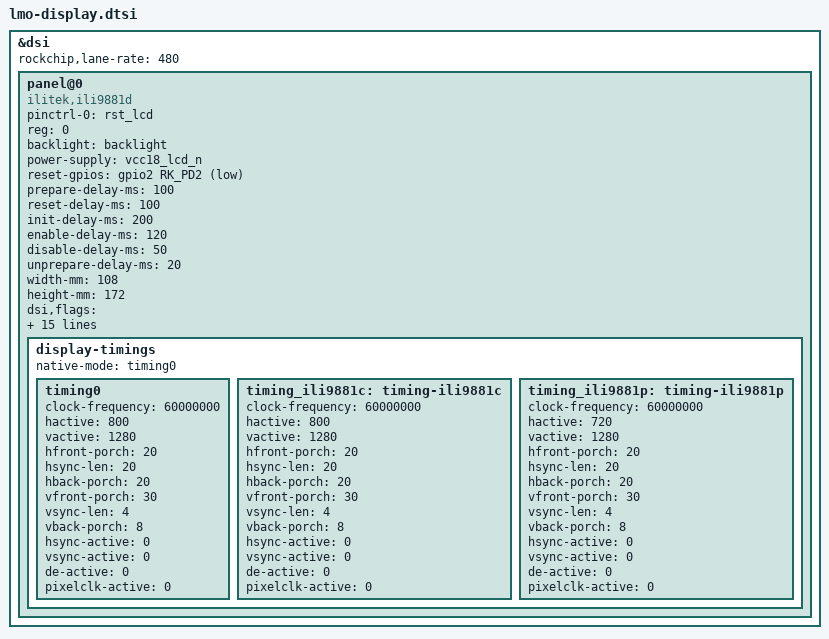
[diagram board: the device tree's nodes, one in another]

&dsi {
	status = "okay";

	rockchip,lane-rate = <480>;
	panel@0 {
		compatible = "ilitek,ili9881d", "simple-panel-dsi";
		pinctrl-names = "default";
		pinctrl-0 = <&rst_lcd>;
		reg = <0>;
		backlight = <&backlight>;
		power-supply = <&vcc18_lcd_n>;
		reset-gpios = <&gpio2 RK_PD2 GPIO_ACTIVE_LOW>;
		prepare-delay-ms = <100>;
		reset-delay-ms = <100>;
		init-delay-ms = <200>;
		enable-delay-ms = <120>;
		disable-delay-ms = <50>;
		unprepare-delay-ms = <20>;

		width-mm = <108>;
		height-mm = <172>;

		dsi,flags = <(MIPI_DSI_MODE_VIDEO | MIPI_DSI_MODE_VIDEO_BURST |
			      MIPI_DSI_MODE_LPM | MIPI_DSI_MODE_NO_EOT_PACKET)>;
		dsi,format = <MIPI_DSI_FMT_RGB888>;
		dsi,lanes = <4>;

		panel-init-sequence = [
			39 00 04 FF 98 81 03
			15 00 02 01 00
			15 00 02 02 00
			15 00 02 03 73
			15 00 02 04 D7
			15 00 02 05 00
			15 00 02 06 08
			15 00 02 07 11
			15 00 02 08 00
			15 00 02 09 3F
			15 00 02 0A 00
			15 00 02 0B 00
			15 00 02 0C 00
			15 00 02 0D 00
			15 00 02 0E 00
			15 00 02 0F 3F
			15 00 02 10 3F
			15 00 02 11 00
			15 00 02 12 00
			15 00 02 13 00
			15 00 02 14 00
			15 00 02 15 00
			15 00 02 16 00
			15 00 02 17 00
			15 00 02 18 00
			15 00 02 19 00
			15 00 02 1A 00
			15 00 02 1B 00
			15 00 02 1C 00
			15 00 02 1D 00
			15 00 02 1E 40
			15 00 02 1F 80
			15 00 02 20 06
			15 00 02 21 01
			15 00 02 22 00
			15 00 02 23 00
			15 00 02 24 00
			15 00 02 25 00
			15 00 02 26 00
			15 00 02 27 00
			15 00 02 28 33
			15 00 02 29 33
			15 00 02 2A 00
			15 00 02 2B 00
			15 00 02 2C 00
			15 00 02 2D 00
			15 00 02 2E 00
			15 00 02 2F 00
			15 00 02 30 00
			15 00 02 31 00
			15 00 02 32 00
			15 00 02 33 00
			15 00 02 34 00
			15 00 02 35 00
			15 00 02 36 00
			15 00 02 37 00
			15 00 02 38 00
			15 00 02 39 00
			15 00 02 3A 00
			15 00 02 3B 00
			15 00 02 3C 00
			15 00 02 3D 00
			15 00 02 3E 00
			15 00 02 3F 00
			15 00 02 40 00
			15 00 02 41 00
			15 00 02 42 00
			15 00 02 43 00
			15 00 02 44 00
			15 00 02 50 01
			15 00 02 51 23
			15 00 02 52 44
			15 00 02 53 67
			15 00 02 54 89
			15 00 02 55 AB
			15 00 02 56 01
			15 00 02 57 23
			15 00 02 58 45
			15 00 02 59 67
			15 00 02 5A 89
			15 00 02 5B AB
			15 00 02 5C CD
			15 00 02 5D EF
			15 00 02 5E 00
			15 00 02 5F 0C
			15 00 02 60 0C
			15 00 02 61 0F
			15 00 02 62 0F
			15 00 02 63 0E
			15 00 02 64 0E
			15 00 02 65 06
			15 00 02 66 07
			15 00 02 67 0D
			15 00 02 68 02
			15 00 02 69 02
			15 00 02 6A 02
			15 00 02 6B 02
			15 00 02 6C 02
			15 00 02 6D 02
			15 00 02 6E 0D
			15 00 02 6F 02
			15 00 02 70 02
			15 00 02 71 05
			15 00 02 72 01
			15 00 02 73 08
			15 00 02 74 00
			15 00 02 75 0C
			15 00 02 76 0C
			15 00 02 77 0F
			15 00 02 78 0F
			15 00 02 79 0E
			15 00 02 7A 0E
			15 00 02 7B 06
			15 00 02 7C 07
			15 00 02 7D 0D
			15 00 02 7E 02
			15 00 02 7F 02
			15 00 02 80 02
			15 00 02 81 02
			15 00 02 82 02
			15 00 02 83 02
			15 00 02 84 0D
			15 00 02 85 02
			15 00 02 86 02
			15 00 02 87 05
			15 00 02 88 01
			15 00 02 89 08
			15 00 02 8A 00
			39 00 04 FF 98 81 04
			15 00 02 6E 3B
			15 00 02 6F 57
			15 00 02 3A A4
			15 00 02 8D 1F
			15 00 02 87 BA
			15 00 02 B2 D1
			15 00 02 88 0B
			15 00 02 38 01
			15 00 02 39 00
			15 00 02 B5 07
			15 00 02 31 75
			15 00 02 3B 98
			39 00 04 FF 98 81 01
			15 00 02 22 0A
			15 00 02 31 09
			15 00 02 53 62
			15 00 02 55 40
			15 00 02 50 86
			15 00 02 51 82
			15 00 02 60 27
			15 00 02 62 20
			15 00 02 A0 00
			15 00 02 A1 11
			15 00 02 A2 1F
			15 00 02 A3 13
			15 00 02 A4 14
			15 00 02 A5 28
			15 00 02 A6 1D
			15 00 02 A7 1F
			15 00 02 A8 7A
			15 00 02 A9 1C
			15 00 02 AA 2A
			15 00 02 AB 69
			15 00 02 AC 1A
			15 00 02 AD 18
			15 00 02 AE 4D
			15 00 02 AF 22
			15 00 02 B0 29
			15 00 02 B1 4C
			15 00 02 B2 5B
			15 00 02 B3 23
			15 00 02 C0 00
			15 00 02 C1 12
			15 00 02 C2 1F
			15 00 02 C3 12
			15 00 02 C4 15
			15 00 02 C5 29
			15 00 02 C6 1D
			15 00 02 C7 1E
			15 00 02 C8 78
			15 00 02 C9 1D
			15 00 02 CA 29
			15 00 02 CB 69
			15 00 02 CC 19
			15 00 02 CD 18
			15 00 02 CE 4C
			15 00 02 CF 21
			15 00 02 D0 29
			15 00 02 D1 4C
			15 00 02 D2 5B
			15 00 02 D3 23
			39 00 04 FF 98 81 00
			15 C8 02 11 00
			15 C8 02 29 00
		];

		panel-init-sequence-jd9365da = [
			15 00 02 E1 93
			15 00 02 E2 65
			15 00 02 E3 F8
			15 00 02 80 03
			15 00 02 E0 01
			15 00 02 00 00
			15 00 02 01 2A
			15 00 02 03 00
			15 00 02 04 30
			15 00 02 17 00
			15 00 02 18 E7
			15 00 02 19 00
			15 00 02 1A 00
			15 00 02 1B E7
			15 00 02 1C 00
			15 00 02 35 23
			15 00 02 37 09
			15 00 02 38 04
			15 00 02 39 08
			15 00 02 3A 12
			15 00 02 3C 78
			15 00 02 3D FF
			15 00 02 3E FF
			15 00 02 3F FF
			15 00 02 40 06
			15 00 02 41 A0
			15 00 02 43 14
			15 00 02 44 0F
			15 00 02 45 30
			15 00 02 4B 04
			15 00 02 55 02
			15 00 02 57 65
			15 00 02 59 0A
			15 00 02 5A 28
			15 00 02 5B 15
			15 00 02 5D 7C
			15 00 02 5E 5A
			15 00 02 5F 45
			15 00 02 60 36
			15 00 02 61 2F
			15 00 02 62 20
			15 00 02 63 24
			15 00 02 64 0F
			15 00 02 65 2C
			15 00 02 66 2E
			15 00 02 67 31
			15 00 02 68 52
			15 00 02 69 40
			15 00 02 6A 49
			15 00 02 6B 3E
			15 00 02 6C 3B
			15 00 02 6D 30
			15 00 02 6E 21
			15 00 02 6F 0C
			15 00 02 70 7C
			15 00 02 71 5A
			15 00 02 72 45
			15 00 02 73 36
			15 00 02 74 2F
			15 00 02 75 20
			15 00 02 76 24
			15 00 02 77 0F
			15 00 02 78 2C
			15 00 02 79 2E
			15 00 02 7A 31
			15 00 02 7B 52
			15 00 02 7C 40
			15 00 02 7D 49
			15 00 02 7E 3E
			15 00 02 7F 3B
			15 00 02 80 30
			15 00 02 81 21
			15 00 02 82 0C
			15 00 02 E0 02
			15 00 02 00 5F
			15 00 02 01 5F
			15 00 02 02 53
			15 00 02 03 51
			15 00 02 04 4B
			15 00 02 05 49
			15 00 02 06 47
			15 00 02 07 45
			15 00 02 08 41
			15 00 02 09 43
			15 00 02 0A 5F
			15 00 02 0B 5F
			15 00 02 0C 5F
			15 00 02 0D 5F
			15 00 02 0E 5F
			15 00 02 0F 5F
			15 00 02 10 5F
			15 00 02 11 5F
			15 00 02 12 5F
			15 00 02 13 5F
			15 00 02 14 5F
			15 00 02 15 5F
			15 00 02 16 5F
			15 00 02 17 5F
			15 00 02 18 52
			15 00 02 19 50
			15 00 02 1A 4A
			15 00 02 1B 48
			15 00 02 1C 46
			15 00 02 1D 44
			15 00 02 1E 40
			15 00 02 1F 42
			15 00 02 20 5F
			15 00 02 21 5F
			15 00 02 22 5F
			15 00 02 23 5F
			15 00 02 24 5F
			15 00 02 25 5F
			15 00 02 26 5F
			15 00 02 27 5F
			15 00 02 28 5F
			15 00 02 29 5F
			15 00 02 2A 5F
			15 00 02 2B 5F
			15 00 02 2C 1F
			15 00 02 2D 1F
			15 00 02 2E 00
			15 00 02 2F 02
			15 00 02 30 08
			15 00 02 31 0A
			15 00 02 32 04
			15 00 02 33 06
			15 00 02 34 12
			15 00 02 35 10
			15 00 02 36 1F
			15 00 02 37 1F
			15 00 02 38 1F
			15 00 02 39 1F
			15 00 02 3A 1F
			15 00 02 3B 1F
			15 00 02 3C 1F
			15 00 02 3D 1F
			15 00 02 3E 1F
			15 00 02 3F 1F
			15 00 02 40 1F
			15 00 02 41 1F
			15 00 02 42 1F
			15 00 02 43 1F
			15 00 02 44 01
			15 00 02 45 03
			15 00 02 46 09
			15 00 02 47 0B
			15 00 02 48 05
			15 00 02 49 07
			15 00 02 4A 13
			15 00 02 4B 11
			15 00 02 4C 1F
			15 00 02 4D 1F
			15 00 02 4E 1F
			15 00 02 4F 1F
			15 00 02 50 1F
			15 00 02 51 1F
			15 00 02 52 1F
			15 00 02 53 1F
			15 00 02 54 1F
			15 00 02 55 1F
			15 00 02 56 1F
			15 00 02 57 1F
			15 00 02 58 40
			15 00 02 59 00
			15 00 02 5A 00
			15 00 02 5B 30
			15 00 02 5C 09
			15 00 02 5D 30
			15 00 02 5E 01
			15 00 02 5F 02
			15 00 02 60 30
			15 00 02 61 03
			15 00 02 62 04
			15 00 02 63 1C
			15 00 02 64 6A
			15 00 02 65 75
			15 00 02 66 0d
			15 00 02 67 72
			15 00 02 68 0c
			15 00 02 69 1C
			15 00 02 6A 6A
			15 00 02 6B 08
			15 00 02 6C 00
			15 00 02 6D 00
			15 00 02 6E 00
			15 00 02 6F 88
			15 00 02 70 00
			15 00 02 71 00
			15 00 02 72 06
			15 00 02 73 7B
			15 00 02 74 00
			15 00 02 75 BB
			15 00 02 76 01
			15 00 02 77 0D
			15 00 02 78 24
			15 00 02 79 00
			15 00 02 7A 00
			15 00 02 7B 00
			15 00 02 7C 00
			15 00 02 7D 03
			15 00 02 7E 7B
			15 00 02 E0 04
			15 00 02 00 0E
			15 00 02 02 B3
			15 00 02 0E 4A
			15 00 02 E0 00
			05 C8 01 11
			05 14 01 29
		];

		panel-init-sequence-jd9365d = [
			15 00 02 E0 00

			15 00 02 E1 93
			15 00 02 E2 65
			15 00 02 E3 F8
			15 00 02 80 03

			15 00 02 E0 01

			15 00 02 00 00
			15 00 02 01 3C
			15 00 02 03 00
			15 00 02 04 3C

			15 00 02 0C 74
			15 00 02 17 00
			15 00 02 18 F7
			15 00 02 19 01
			15 00 02 1A 00
			15 00 02 1B F7
			15 00 02 1C 01

			15 00 02 24 F1

			15 00 02 35 23

			15 00 02 37 09

			15 00 02 38 04
			15 00 02 39 00
			15 00 02 3A 01
			15 00 02 3C 70
			15 00 02 3D FF
			15 00 02 3E FF
			15 00 02 3F 7F

			15 00 02 40 06
			15 00 02 41 A0
			15 00 02 43 1E
			15 00 02 44 0B
			15 00 02 45 28

			15 00 02 55 01
			15 00 02 57 A9
			15 00 02 59 0A
			15 00 02 5A 2D
			15 00 02 5B 1A
			15 00 02 5C 15

			15 00 02 5D 7F
			15 00 02 5E 69
			15 00 02 5F 59
			15 00 02 60 4C
			15 00 02 61 47
			15 00 02 62 38
			15 00 02 63 3D
			15 00 02 64 27
			15 00 02 65 41
			15 00 02 66 40
			15 00 02 67 40
			15 00 02 68 5B
			15 00 02 69 46
			15 00 02 6A 49
			15 00 02 6B 3A
			15 00 02 6C 34
			15 00 02 6D 25
			15 00 02 6E 15
			15 00 02 6F 02
			15 00 02 70 7F
			15 00 02 71 69
			15 00 02 72 59
			15 00 02 73 4C
			15 00 02 74 47
			15 00 02 75 38
			15 00 02 76 3D
			15 00 02 77 27
			15 00 02 78 41
			15 00 02 79 40
			15 00 02 7A 40
			15 00 02 7B 5B
			15 00 02 7C 46
			15 00 02 7D 49
			15 00 02 7E 3A
			15 00 02 7F 34
			15 00 02 80 25
			15 00 02 81 15
			15 00 02 82 02

			15 00 02 E0 02

			15 00 02 00 50
			15 00 02 01 5F
			15 00 02 02 5F
			15 00 02 03 52
			15 00 02 04 77
			15 00 02 05 57
			15 00 02 06 5F
			15 00 02 07 4E
			15 00 02 08 4C
			15 00 02 09 5F
			15 00 02 0A 4A
			15 00 02 0B 48
			15 00 02 0C 5F
			15 00 02 0D 46
			15 00 02 0E 44
			15 00 02 0F 40
			15 00 02 10 5F
			15 00 02 11 5F
			15 00 02 12 5F
			15 00 02 13 5F
			15 00 02 14 5F
			15 00 02 15 5F

			15 00 02 16 51
			15 00 02 17 5F
			15 00 02 18 5F
			15 00 02 19 53
			15 00 02 1A 77
			15 00 02 1B 57
			15 00 02 1C 5F
			15 00 02 1D 4F
			15 00 02 1E 4D
			15 00 02 1F 5F
			15 00 02 20 4B
			15 00 02 21 49
			15 00 02 22 5F
			15 00 02 23 47
			15 00 02 24 45
			15 00 02 25 41
			15 00 02 26 5F
			15 00 02 27 5F
			15 00 02 28 5F
			15 00 02 29 5F
			15 00 02 2A 5F
			15 00 02 2B 5F

			15 00 02 2C 01
			15 00 02 2D 1F
			15 00 02 2E 1F
			15 00 02 2F 13
			15 00 02 30 17
			15 00 02 31 17
			15 00 02 32 1F
			15 00 02 33 0D
			15 00 02 34 0F
			15 00 02 35 1F
			15 00 02 36 05
			15 00 02 37 07
			15 00 02 38 1F
			15 00 02 39 09
			15 00 02 3A 0B
			15 00 02 3B 11
			15 00 02 3C 1F
			15 00 02 3D 1F
			15 00 02 3E 1F
			15 00 02 3F 1F
			15 00 02 40 1F
			15 00 02 41 1F

			15 00 02 42 00
			15 00 02 43 1F
			15 00 02 44 1F
			15 00 02 45 12
			15 00 02 46 17
			15 00 02 47 17
			15 00 02 48 1F
			15 00 02 49 0C
			15 00 02 4A 0E
			15 00 02 4B 1F
			15 00 02 4C 04
			15 00 02 4D 06
			15 00 02 4E 1F
			15 00 02 4F 08
			15 00 02 50 0A
			15 00 02 51 10
			15 00 02 52 1F
			15 00 02 53 1F
			15 00 02 54 1F
			15 00 02 55 1F
			15 00 02 56 1F
			15 00 02 57 1F

			15 00 02 58 40
			15 00 02 5B 10
			15 00 02 5C 06
			15 00 02 5D 40
			15 00 02 5E 00
			15 00 02 5F 00
			15 00 02 60 40
			15 00 02 61 03
			15 00 02 62 04
			15 00 02 63 6C
			15 00 02 64 6C
			15 00 02 65 75
			15 00 02 66 08
			15 00 02 67 B4
			15 00 02 68 08
			15 00 02 69 6C
			15 00 02 6A 6C
			15 00 02 6B 0C
			15 00 02 6D 00
			15 00 02 6E 00
			15 00 02 6F 88
			15 00 02 75 BB
			15 00 02 76 00
			15 00 02 77 05
			15 00 02 78 2A

			15 00 02 E0 04
			15 00 02 09 11
			15 00 02 0E 48
			15 00 02 2B 08
			15 00 02 2D 03
			15 00 02 2E 03

			15 00 02 E0 00

			15 78 02 11 00
			15 05 02 29 00
		];

		panel-init-sequence-ili9881c = [
			39 00 04 FF 98 81 03
			15 00 02 01 00
			15 00 02 02 00
			15 00 02 03 73
			15 00 02 04 00
			15 00 02 05 00
			15 00 02 06 08
			15 00 02 07 00
			15 00 02 08 00
			15 00 02 09 00
			15 00 02 0A 01
			15 00 02 0B 01
			15 00 02 0C 00
			15 00 02 0D 01
			15 00 02 0E 01
			15 00 02 0F 00
			15 00 02 10 00
			15 00 02 11 00
			15 00 02 12 00
			15 00 02 13 1F
			15 00 02 14 1F
			15 00 02 15 00
			15 00 02 16 00
			15 00 02 17 00
			15 00 02 18 00
			15 00 02 19 00
			15 00 02 1A 00
			15 00 02 1B 00
			15 00 02 1C 00
			15 00 02 1D 00
			15 00 02 1E 40
			15 00 02 1F C0
			15 00 02 20 06
			15 00 02 21 01
			15 00 02 22 06
			15 00 02 23 01
			15 00 02 24 88
			15 00 02 25 88
			15 00 02 26 00
			15 00 02 27 00
			15 00 02 28 3B
			15 00 02 29 03
			15 00 02 2A 00
			15 00 02 2B 00
			15 00 02 2C 00
			15 00 02 2D 00
			15 00 02 2E 00
			15 00 02 2F 00
			15 00 02 30 00
			15 00 02 31 00
			15 00 02 32 00
			15 00 02 33 00
			15 00 02 34 00
			15 00 02 35 00
			15 00 02 36 00
			15 00 02 37 00
			15 00 02 38 00
			15 00 02 39 00
			15 00 02 3A 00
			15 00 02 3B 00
			15 00 02 3C 00
			15 00 02 3D 00
			15 00 02 3E 00
			15 00 02 3F 00
			15 00 02 40 00
			15 00 02 41 00
			15 00 02 42 00
			15 00 02 43 00
			15 00 02 44 00
			15 00 02 50 01
			15 00 02 51 23
			15 00 02 52 45
			15 00 02 53 67
			15 00 02 54 89
			15 00 02 55 AB
			15 00 02 56 01
			15 00 02 57 23
			15 00 02 58 45
			15 00 02 59 67
			15 00 02 5A 89
			15 00 02 5B AB
			15 00 02 5C CD
			15 00 02 5D EF
			15 00 02 5E 00
			15 00 02 5F 01
			15 00 02 60 01
			15 00 02 61 06
			15 00 02 62 06
			15 00 02 63 07
			15 00 02 64 07
			15 00 02 65 00
			15 00 02 66 00
			15 00 02 67 02
			15 00 02 68 02
			15 00 02 69 05
			15 00 02 6A 05
			15 00 02 6B 02
			15 00 02 6C 0D
			15 00 02 6D 0D
			15 00 02 6E 0C
			15 00 02 6F 0C
			15 00 02 70 0F
			15 00 02 71 0F
			15 00 02 72 0E
			15 00 02 73 0E
			15 00 02 74 02
			15 00 02 75 01
			15 00 02 76 01
			15 00 02 77 06
			15 00 02 78 06
			15 00 02 79 07
			15 00 02 7A 07
			15 00 02 7B 00
			15 00 02 7C 00
			15 00 02 7D 02
			15 00 02 7E 02
			15 00 02 7F 05
			15 00 02 80 05
			15 00 02 81 02
			15 00 02 82 0D
			15 00 02 83 0D
			15 00 02 84 0C
			15 00 02 85 0C
			15 00 02 86 0F
			15 00 02 87 0F
			15 00 02 88 0E
			15 00 02 89 0E
			15 00 02 8A 02
			39 00 04 FF 98 81 04
			15 00 02 6C 15
			15 00 02 6E 2A
			15 00 02 6F 33
			15 00 02 8D 1B
			15 00 02 87 BA
			15 00 02 3A 24
			15 00 02 26 76
			15 00 02 B2 D1
			39 00 04 FF 98 81 01
			15 00 02 22 0A
			15 00 02 31 00                  
			15 00 02 43 66
			15 00 02 53 42
			15 00 02 50 87
			15 00 02 51 82
			15 00 02 60 15
			15 00 02 61 01
			15 00 02 62 0C
			15 00 02 63 00
			15 00 02 A0 00
			15 00 02 A1 13
			15 00 02 A2 23
			15 00 02 A3 14
			15 00 02 A4 16
			15 00 02 A5 29
			15 00 02 A6 1E
			15 00 02 A7 1D
			15 00 02 A8 86
			15 00 02 A9 1E
			15 00 02 AA 29
			15 00 02 AB 74
			15 00 02 AC 19
			15 00 02 AD 17
			15 00 02 AE 4B
			15 00 02 AF 20
			15 00 02 B0 26
			15 00 02 B1 4C
			15 00 02 B2 5D
			15 00 02 B3 3F
			15 00 02 C0 00
			15 00 02 C1 13
			15 00 02 C2 23
			15 00 02 C3 14
			15 00 02 C4 16
			15 00 02 C5 29
			15 00 02 C6 1E
			15 00 02 C7 1D
			15 00 02 C8 86
			15 00 02 C9 1E
			15 00 02 CA 29
			15 00 02 CB 74
			15 00 02 CC 19
			15 00 02 CD 17
			15 00 02 CE 4B
			15 00 02 CF 20
			15 00 02 D0 26
			15 00 02 D1 4C
			15 00 02 D2 5D
			15 00 02 D3 3F
			39 00 04 FF 98 81 00
			15 00 02 35 00
			05 78 01 11
			05 14 01 29
		];

		panel-init-sequence-ili9881p = [//720x1280
			39 00 04 FF 98 81 01
			15 00 02 01 00
			15 00 02 02 00
			15 00 02 03 56
			15 00 02 04 13
			15 00 02 05 13
			15 00 02 06 0a
			15 00 02 07 05
			15 00 02 08 05
			15 00 02 09 1D
			15 00 02 0a 01
			15 00 02 0b 00
			15 00 02 0c 3F
			15 00 02 0d 29
			15 00 02 0e 29
			15 00 02 0f 1D
			15 00 02 10 1D
			15 00 02 11 00
			15 00 02 12 00
			15 00 02 13 08
			15 00 02 14 08
			15 00 02 15 00
			15 00 02 16 00
			15 00 02 17 00
			15 00 02 18 00
			15 00 02 19 00
			15 00 02 1a 00
			15 00 02 1b 00
			15 00 02 1c 00
			15 00 02 1d 00
			15 00 02 1e 40
			15 00 02 1f 88
			15 00 02 20 08
			15 00 02 21 01
			15 00 02 22 00
			15 00 02 23 00
			15 00 02 24 00
			15 00 02 25 00
			15 00 02 26 00
			15 00 02 27 00
			15 00 02 28 33
			15 00 02 29 03
			15 00 02 2a 00
			15 00 02 2b 00
			15 00 02 2c 00
			15 00 02 2d 00
			15 00 02 2e 00
			15 00 02 2f 00
			15 00 02 30 00
			15 00 02 31 00
			15 00 02 32 00
			15 00 02 33 00
			15 00 02 34 00
			15 00 02 35 00
			15 00 02 36 00
			15 00 02 37 00
			15 00 02 38 00
			15 00 02 39 0f
			15 00 02 3a 2a
			15 00 02 3b 00
			15 00 02 3c 00
			15 00 02 3d 00
			15 00 02 3e 00
			15 00 02 3f 00
			15 00 02 40 00
			15 00 02 41 e0
			15 00 02 42 40
			15 00 02 43 0f
			15 00 02 44 11
			15 00 02 45 a8
			15 00 02 46 00
			15 00 02 47 08
			15 00 02 48 00
			15 00 02 49 01
			15 00 02 4a 00
			15 00 02 4b 00
			15 00 02 4c b2
			15 00 02 4d 22
			15 00 02 4e 07
			15 00 02 4f f1
			15 00 02 50 29
			15 00 02 51 72
			15 00 02 52 25
			15 00 02 53 b2
			15 00 02 54 22
			15 00 02 55 22
			15 00 02 56 22
			15 00 02 57 a2
			15 00 02 58 22
			15 00 02 59 06
			15 00 02 5a e1
			15 00 02 5b 28
			15 00 02 5c 62
			15 00 02 5d 24
			15 00 02 5e a2
			15 00 02 5f 22
			15 00 02 60 22
			15 00 02 61 22
			15 00 02 62 ee
			15 00 02 63 02
			15 00 02 64 0b
			15 00 02 65 02
			15 00 02 66 02
			15 00 02 67 0F
			15 00 02 68 00
			15 00 02 69 01
			15 00 02 6a 07
			15 00 02 6b 55
			15 00 02 6c 02
			15 00 02 6d 02
			15 00 02 6e 5b
			15 00 02 6f 59
			15 00 02 70 02
			15 00 02 71 02
			15 00 02 72 57
			15 00 02 73 02
			15 00 02 74 02
			15 00 02 75 02
			15 00 02 76 02
			15 00 02 77 02
			15 00 02 78 02
			15 00 02 79 02
			15 00 02 7a 0a
			15 00 02 7b 02
			15 00 02 7c 02
			15 00 02 7d 0E
			15 00 02 7e 00
			15 00 02 7f 01
			15 00 02 80 06
			15 00 02 81 54
			15 00 02 82 02
			15 00 02 83 02
			15 00 02 84 5a
			15 00 02 85 58
			15 00 02 86 02
			15 00 02 87 02
			15 00 02 88 56
			15 00 02 89 02
			15 00 02 8a 02
			15 00 02 8b 02
			15 00 02 8c 02
			15 00 02 8d 02
			15 00 02 8e 02
			15 00 02 8f 44
			15 00 02 90 44
			39 00 04 FF 98 81 02
			15 00 02 01 50
			15 00 02 15 10
			15 00 02 42 01
			39 00 15 57 00 1A 29 13 17 2B 1F 20 8E 1E 2A 76 1A 17 4B 21 27 45 53 24
			39 00 15 6B 00 1A 29 13 17 2B 1F 20 8E 1E 2A 76 1A 17 4B 21 27 45 53 24
			39 00 04 FF 98 81 05
			15 00 02 03 00
			15 00 02 04 1E
			15 00 02 1A 50
			15 00 02 1B 09
			15 00 02 1E 11
			15 00 02 26 0E
			15 00 02 38 A0
			15 00 02 4C 11
			15 00 02 4D 22
			15 00 02 54 28
			15 00 02 55 25
			15 00 02 78 01
			15 00 02 A9 C0
			15 00 02 B1 70
			15 00 02 B2 70
			39 00 04 FF 98 81 06
			15 00 02 01 03
			15 00 02 2B 0A
			15 00 02 04 70
			15 00 02 C0 7F
			15 00 02 C1 2A
			39 00 04 FF 98 81 00
			15 C8 02 11 00
			15 14 02 29 00
			15 00 02 35 00
			15 00 02 36 00
		];

		panel-exit-sequence = [
			15 00 02 28 00
			15 00 02 10 00
		];

		display-timings {
			native-mode = <&timing0>;

			timing0: timing0 {
				clock-frequency = <60000000>;
				hactive = <800>;
				vactive = <1280>;
				hfront-porch = <20>;
				hsync-len = <20>;
				hback-porch = <20>;
				vfront-porch = <30>;
				vsync-len = <4>;
				vback-porch = <8>;
				hsync-active = <0>;
				vsync-active = <0>;
				de-active = <0>;
				pixelclk-active = <0>;
			};

			timing_ili9881c: timing-ili9881c {
				clock-frequency = <60000000>;
				hactive = <800>;
				vactive = <1280>;
				hfront-porch = <20>;
				hsync-len = <20>;
				hback-porch = <20>;
				vfront-porch = <30>;
				vsync-len = <4>;
				vback-porch = <8>;
				hsync-active = <0>;
				vsync-active = <0>;
				de-active = <0>;
				pixelclk-active = <0>;
			};

			timing_ili9881p: timing-ili9881p {
				clock-frequency = <60000000>;
				hactive = <720>;
				vactive = <1280>;
				hfront-porch = <20>;
				hsync-len = <20>;
				hback-porch = <20>;
				vfront-porch = <30>;
				vsync-len = <4>;
				vback-porch = <8>;
				hsync-active = <0>;
				vsync-active = <0>;
				de-active = <0>;
				pixelclk-active = <0>;
			};
		};
	};
};
